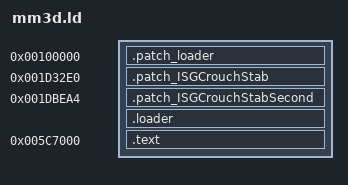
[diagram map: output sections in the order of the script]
OUTPUT_FORMAT("elf32-littlearm", "elf32-littlearm", "elf32-littlearm")
OUTPUT_ARCH(arm)
ENTRY(loader_patch)
SECTIONS
{
	. = 0x100000;
	.patch_loader 0x100000 : {
		*(.patch_loader)
	}

    .patch_ISGCrouchStab 0x1D32E0 : {
            *(.patch_ISGCrouchStab)
    }

    .patch_ISGCrouchStabSecond 0x1DBEA4 : {
            *(.patch_ISGCrouchStab)
    }

	. = 0x4C99A8;
	. = ALIGN(4);
	.loader : {
		*(.loader*)
	}

	. = 0x005C7000;
    .text : {
        __text_start = . ;
        *(.text)
        *(.text.*)
        *(.rodata)
        *(.data)
        *(.bss)
        *(COMMON)
		rCustomMessages = . ;
        __text_end  = . ;
    }
}
